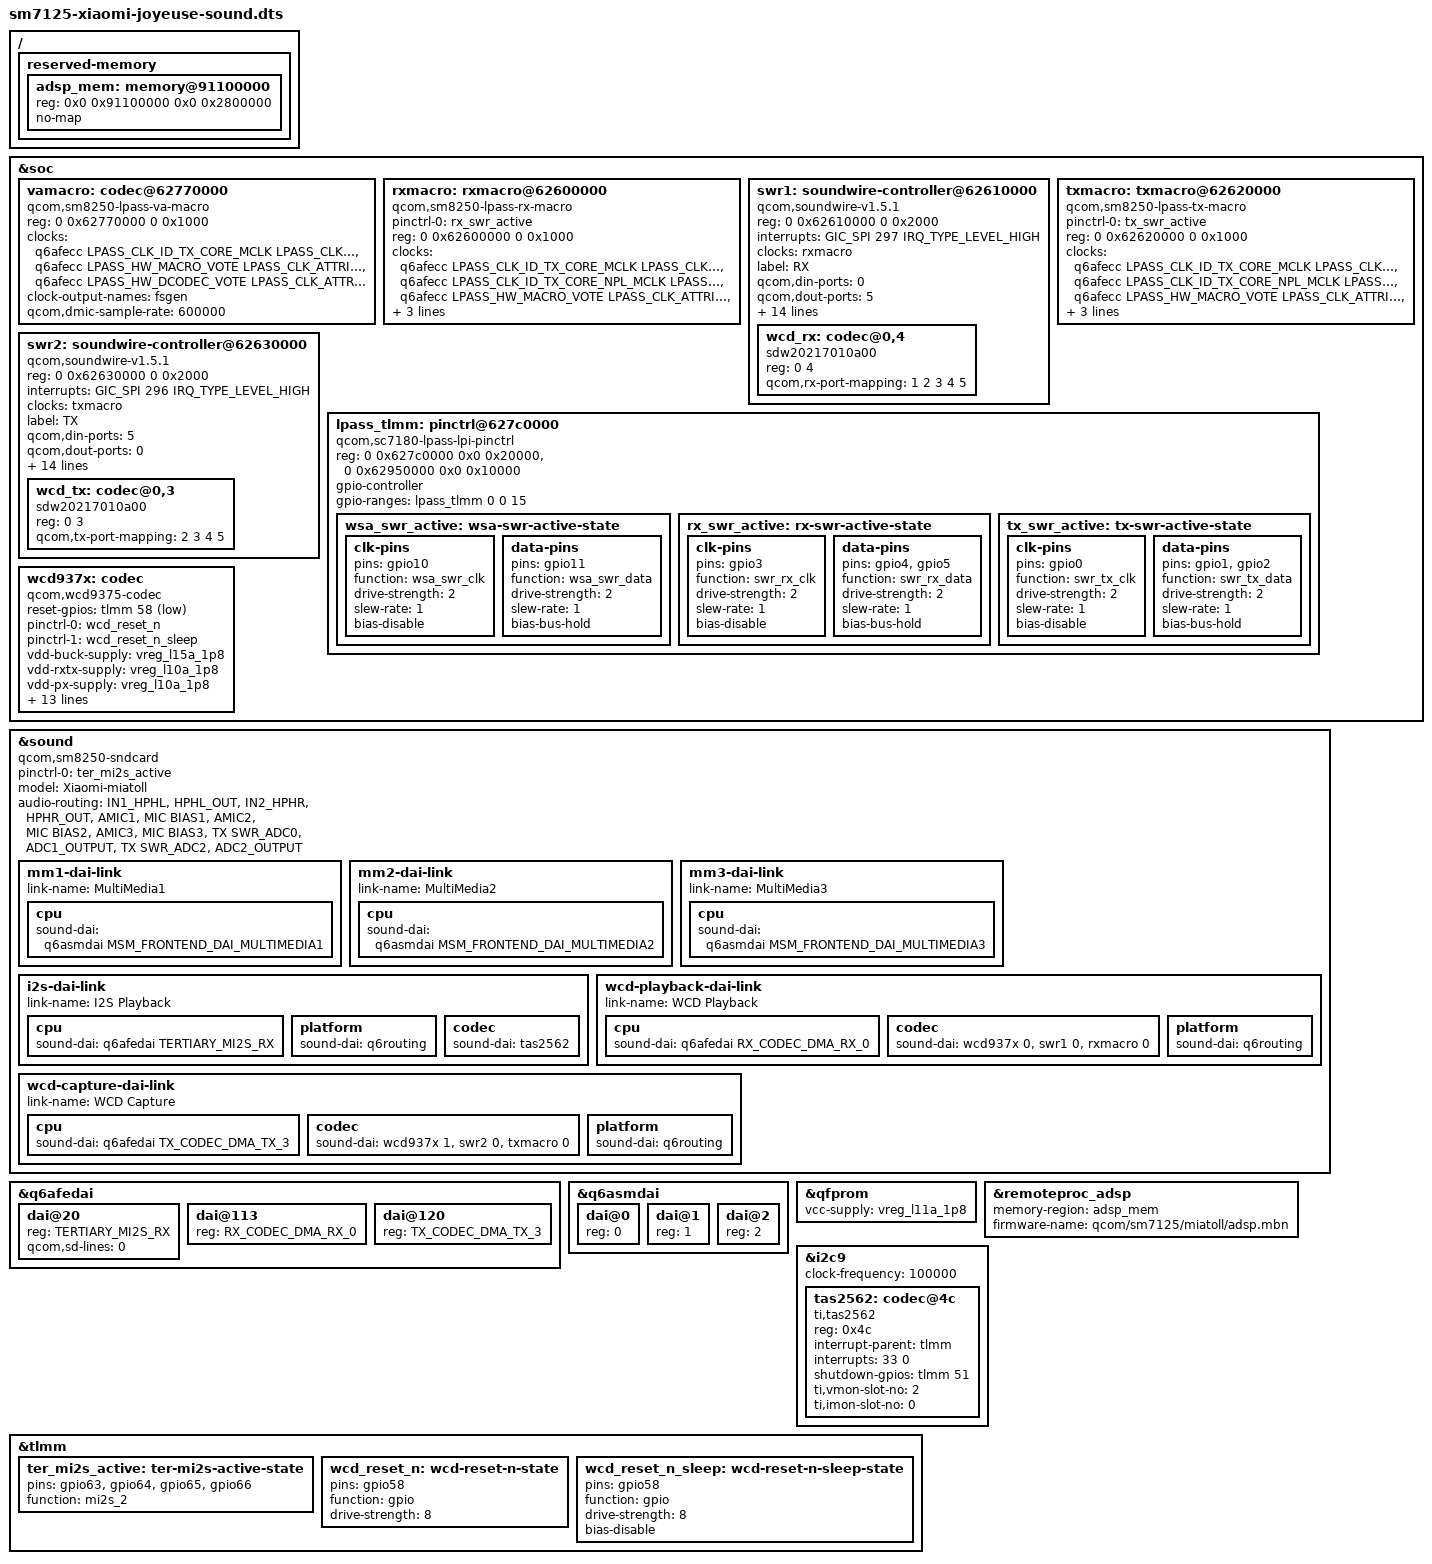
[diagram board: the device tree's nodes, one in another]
#ifndef SM7125_XIAOMI_JOYEUSE_SOUND_DTS
#define SM7125_XIAOMI_JOYEUSE_SOUND_DTS

#include "dt-bindings/sound/qcom,q6asm.h"

#include "sm7125-xiaomi-joyeuse.dts"

/ {
	reserved-memory {
                adsp_mem: memory@91100000 {
                        reg = <0x0 0x91100000 0x0 0x2800000>;
                        no-map;
                };		
	};
};

/* this should go to sc7180.dtsi */
&soc {
	vamacro: codec@62770000 {
		compatible = "qcom,sm8250-lpass-va-macro";
		reg = <0 0x62770000 0 0x1000>;
		clocks = <&q6afecc LPASS_CLK_ID_TX_CORE_MCLK LPASS_CLK_ATTRIBUTE_COUPLE_NO>,
			<&q6afecc LPASS_HW_MACRO_VOTE LPASS_CLK_ATTRIBUTE_COUPLE_NO>,
			<&q6afecc LPASS_HW_DCODEC_VOTE LPASS_CLK_ATTRIBUTE_COUPLE_NO>;

		clock-names = "mclk", "macro", "dcodec";

		#clock-cells = <0>;
		clock-output-names = "fsgen";
		#sound-dai-cells = <1>;
	};

	rxmacro: rxmacro@62600000 {
		pinctrl-names = "default";
		pinctrl-0 = <&rx_swr_active>;
		compatible = "qcom,sm8250-lpass-rx-macro";
		reg = <0 0x62600000 0 0x1000>;
		status = "disabled";

		clocks = <&q6afecc LPASS_CLK_ID_TX_CORE_MCLK LPASS_CLK_ATTRIBUTE_COUPLE_NO>,
				<&q6afecc LPASS_CLK_ID_TX_CORE_NPL_MCLK LPASS_CLK_ATTRIBUTE_COUPLE_NO>,
				<&q6afecc LPASS_HW_MACRO_VOTE LPASS_CLK_ATTRIBUTE_COUPLE_NO>,
				<&q6afecc LPASS_HW_DCODEC_VOTE LPASS_CLK_ATTRIBUTE_COUPLE_NO>,
				<&vamacro>;

		clock-names = "mclk", "npl", "macro", "dcodec", "fsgen";

		#clock-cells = <0>;
		clock-output-names = "mclk";
		#sound-dai-cells = <1>;
	};

	swr1: soundwire-controller@62610000 {
		reg = <0 0x62610000 0 0x2000>;
		compatible = "qcom,soundwire-v1.5.1";
		status = "disabled";
		interrupts = <GIC_SPI 297 IRQ_TYPE_LEVEL_HIGH>;

		clocks = <&rxmacro>;
		clock-names = "iface";
		label = "RX";

		qcom,din-ports = <0>;
		qcom,dout-ports = <5>;
		qcom,ports-sinterval-low =	/bits/ 8 <0x03 0x1f 0x1f 0x07 0x00>;
		qcom,ports-offset1 =		/bits/ 8 <0x00 0x00 0x0b 0x01 0x00>;
		qcom,ports-offset2 =		/bits/ 8 <0x00 0x00 0x0b 0x00 0x00>;
		qcom,ports-hstart =		/bits/ 8 <0xff 0x03 0xff 0xff 0xff>;
		qcom,ports-hstop =		/bits/ 8 <0xff 0x06 0xff 0xff 0xff>;
		qcom,ports-word-length =	/bits/ 8 <0x01 0x07 0x04 0xff 0xff>;
		qcom,ports-block-pack-mode =	/bits/ 8 <0xff 0x00 0x01 0xff 0xff>;
		qcom,ports-lane-control =	/bits/ 8 <0x01 0x00 0x00 0x00 0x00>;
		qcom,ports-block-group-count =	/bits/ 8 <0xff 0xff 0xff 0xff 0x00>;

		#sound-dai-cells = <1>;
		#address-cells = <2>;
		#size-cells = <0>;
	};

	txmacro: txmacro@62620000 {
		pinctrl-names = "default";
		pinctrl-0 = <&tx_swr_active>;
		compatible = "qcom,sm8250-lpass-tx-macro";
		reg = <0 0x62620000 0 0x1000>;
		status = "disabled";

		clocks = <&q6afecc LPASS_CLK_ID_TX_CORE_MCLK LPASS_CLK_ATTRIBUTE_COUPLE_NO>,
				<&q6afecc LPASS_CLK_ID_TX_CORE_NPL_MCLK LPASS_CLK_ATTRIBUTE_COUPLE_NO>,
				<&q6afecc LPASS_HW_MACRO_VOTE LPASS_CLK_ATTRIBUTE_COUPLE_NO>,
				<&q6afecc LPASS_HW_DCODEC_VOTE LPASS_CLK_ATTRIBUTE_COUPLE_NO>,
				<&vamacro>;

		clock-names = "mclk", "npl", "macro", "dcodec", "fsgen";

		#clock-cells = <0>;
		clock-output-names = "mclk";
		#sound-dai-cells = <1>;
	};

	swr2: soundwire-controller@62630000 {
		reg = <0 0x62630000 0 0x2000>;
		compatible = "qcom,soundwire-v1.5.1";
		status = "disabled";
		interrupts = <GIC_SPI 296 IRQ_TYPE_LEVEL_HIGH>;

		clocks = <&txmacro>;
		clock-names = "iface";
		label = "TX";

		qcom,din-ports = <5>;
		qcom,dout-ports = <0>;
		qcom,ports-sinterval-low =	/bits/ 8 <0xff 0x01 0x01 0x03 0x03>;
		qcom,ports-offset1 =		/bits/ 8 <0xff 0x01 0x00 0x02 0x00>;
		qcom,ports-offset2 =		/bits/ 8 <0xff 0x00 0x00 0x00 0x00>;
		qcom,ports-block-pack-mode =	/bits/ 8 <0xff 0xff 0xff 0xff 0xff>;
		qcom,ports-hstart =		/bits/ 8 <0xff 0xff 0xff 0xff 0xff>;
		qcom,ports-hstop =		/bits/ 8 <0xff 0xff 0xff 0xff 0xff>;
		qcom,ports-word-length =	/bits/ 8 <0xff 0xff 0xff 0xff 0xff>;
		qcom,ports-block-group-count =	/bits/ 8 <0xff 0xff 0xff 0xff 0xff>;
		qcom,ports-lane-control =	/bits/ 8 <0xff 0x00 0x01 0x00 0x01>;

		#sound-dai-cells = <1>;
		#address-cells = <2>;
		#size-cells = <0>;
	};

	lpass_tlmm: pinctrl@627c0000 {
		compatible = "qcom,sc7180-lpass-lpi-pinctrl", "qcom,sc7280-lpass-lpi-pinctrl";
		reg = <0 0x627c0000 0x0 0x20000>,
			<0 0x62950000 0x0 0x10000>;

		gpio-controller;
		#gpio-cells = <2>;
		gpio-ranges = <&lpass_tlmm 0 0 15>;

		//clocks = <&q6afecc LPASS_HW_MACRO_VOTE LPASS_CLK_ATTRIBUTE_COUPLE_NO>,
		//	<&q6afecc LPASS_HW_DCODEC_VOTE LPASS_CLK_ATTRIBUTE_COUPLE_NO>;
		//clock-names = "core", "audio";

		wsa_swr_active: wsa-swr-active-state {
			clk-pins {
				pins = "gpio10";
				function = "wsa_swr_clk";
				drive-strength = <2>;
				slew-rate = <1>;
				bias-disable;
			};

			data-pins {
				pins = "gpio11";
				function = "wsa_swr_data";
				drive-strength = <2>;
				slew-rate = <1>;
				bias-bus-hold;
			};
		};

		rx_swr_active: rx-swr-active-state {
			clk-pins {
				pins = "gpio3";
				function = "swr_rx_clk";
				drive-strength = <2>;
				slew-rate = <1>;
				bias-disable;
			};

			data-pins {
				pins = "gpio4", "gpio5";
				function = "swr_rx_data";
				drive-strength = <2>;
				slew-rate = <1>;
				bias-bus-hold;
			};
		};

		tx_swr_active: tx-swr-active-state {
			clk-pins {
				pins = "gpio0";
				function = "swr_tx_clk";
				drive-strength = <2>;
				slew-rate = <1>;
				bias-disable;
			};

			data-pins {
				pins = "gpio1", "gpio2";
				function = "swr_tx_data";
				drive-strength = <2>;
				slew-rate = <1>;
				bias-bus-hold;
			};
		};
	};

};

&sound {
	compatible = "qcom,sm8250-sndcard";
	pinctrl-0 = <&ter_mi2s_active>;
	pinctrl-names = "default";
	model = "Xiaomi-miatoll";
	audio-routing =
		"IN1_HPHL", "HPHL_OUT",
		"IN2_HPHR", "HPHR_OUT",
		"AMIC1", "MIC BIAS1",
		"AMIC2", "MIC BIAS2",
		"AMIC3", "MIC BIAS3",
		"TX SWR_ADC0", "ADC1_OUTPUT",
		"TX SWR_ADC2", "ADC2_OUTPUT";

	mm1-dai-link {
		link-name = "MultiMedia1";
		cpu {
			sound-dai = <&q6asmdai MSM_FRONTEND_DAI_MULTIMEDIA1>;
		};
	};

	mm2-dai-link {
		link-name = "MultiMedia2";
		cpu {
			sound-dai = <&q6asmdai MSM_FRONTEND_DAI_MULTIMEDIA2>;
		};
	};

	mm3-dai-link {
		link-name = "MultiMedia3";
		cpu {
			sound-dai = <&q6asmdai MSM_FRONTEND_DAI_MULTIMEDIA3>;
		};
	};

	i2s-dai-link {
		link-name = "I2S Playback";
		cpu {
			sound-dai = <&q6afedai TERTIARY_MI2S_RX>;
		};

		platform {
			sound-dai = <&q6routing>;
		};

		codec {
			sound-dai = <&tas2562>;
		};
	};

	wcd-playback-dai-link {
		link-name = "WCD Playback";
		cpu {
			sound-dai = <&q6afedai RX_CODEC_DMA_RX_0>;
		};

		codec {
			sound-dai = <&wcd937x 0>, <&swr1 0>, <&rxmacro 0>;
		};

		platform {
			sound-dai = <&q6routing>;
		};
	};

	wcd-capture-dai-link {
		link-name = "WCD Capture";
		cpu {
			sound-dai = <&q6afedai TX_CODEC_DMA_TX_3>;
		};

		codec {
			sound-dai = <&wcd937x 1>, <&swr2 0>, <&txmacro 0>;
		};

		platform {
			sound-dai = <&q6routing>;
		};
	};
};

&swr1 {
	status = "okay";

	wcd_rx: codec@0,4 {
		compatible = "sdw20217010a00";
		reg = <0 4>;

		qcom,rx-port-mapping = <1 2 3 4 5>;
	};
};

&swr2 {
	status = "okay";
	wcd_tx: codec@0,3 {
		compatible = "sdw20217010a00";
		reg = <0 3>;

		qcom,tx-port-mapping = <2 3 4 5>;
	};
};

&q6afedai {
	dai@20 {
		reg = <TERTIARY_MI2S_RX>;
		qcom,sd-lines = <0>;
	};

	dai@113 {
		reg = <RX_CODEC_DMA_RX_0>;
	};

	dai@120 {
		reg = <TX_CODEC_DMA_TX_3>;
	};
};

&q6asmdai {
	dai@0 {
		reg = <0>;
	};

	dai@1 {
		reg = <1>;
	};

	dai@2 {
		reg = <2>;
	};
};

&qfprom {
	vcc-supply = <&vreg_l11a_1p8>;
};

&rxmacro {
	status = "okay";
};

&txmacro {
	status = "okay";
};

&vamacro {
	qcom,dmic-sample-rate = <600000>;
	status = "okay";
};

&soc {
	wcd937x: codec {
		compatible = "qcom,wcd9375-codec";

		reset-gpios = <&tlmm 58 GPIO_ACTIVE_LOW>;

		pinctrl-names = "default", "sleep";
		pinctrl-0 = <&wcd_reset_n>;
		pinctrl-1 = <&wcd_reset_n_sleep>;

		vdd-buck-supply = <&vreg_l15a_1p8>;
		vdd-rxtx-supply = <&vreg_l10a_1p8>;
		vdd-px-supply = <&vreg_l10a_1p8>;
		vdd-mic-bias-supply = <&vreg_bob>;

		qcom,micbias1-microvolt = <1800000>;
		qcom,micbias2-microvolt = <1800000>;
		qcom,micbias3-microvolt = <1800000>;
		qcom,micbias4-microvolt = <1800000>;
		qcom,mbhc-buttons-vthreshold-microvolt = <75000 150000 237000 500000 500000 500000 500000 500000>;
		qcom,mbhc-headset-vthreshold-microvolt = <1700000>;
		qcom,mbhc-headphone-vthreshold-microvolt = <50000>;
		qcom,rx-device = <&wcd_rx>;
		qcom,tx-device = <&wcd_tx>;

		#sound-dai-cells = <1>;
	};
};

&remoteproc_adsp {
	memory-region = <&adsp_mem>;
	firmware-name = "qcom/sm7125/miatoll/adsp.mbn";
	status = "okay";
};

&i2c9 {
	status = "okay";
	clock-frequency = <100000>;

	tas2562: codec@4c {
			compatible = "ti,tas2562";
			reg = <0x4c>;
			#sound-dai-cells = <0>;
			interrupt-parent = <&tlmm>;
			interrupts = <33 0>;
			shutdown-gpios = <&tlmm 51 0>;
			ti,vmon-slot-no = <2>;
			ti,imon-slot-no = <0>;
	};
};

&tlmm {
	ter_mi2s_active: ter-mi2s-active-state {
		pins = "gpio63", "gpio64", "gpio65", "gpio66";
		function = "mi2s_2";
	};

	wcd_reset_n: wcd-reset-n-state {
		pins = "gpio58";
		function = "gpio";
		drive-strength = <8>;
	};

	wcd_reset_n_sleep: wcd-reset-n-sleep-state {
		pins = "gpio58";
		function = "gpio";
		drive-strength = <8>;
		bias-disable;
	};
};


#endif
